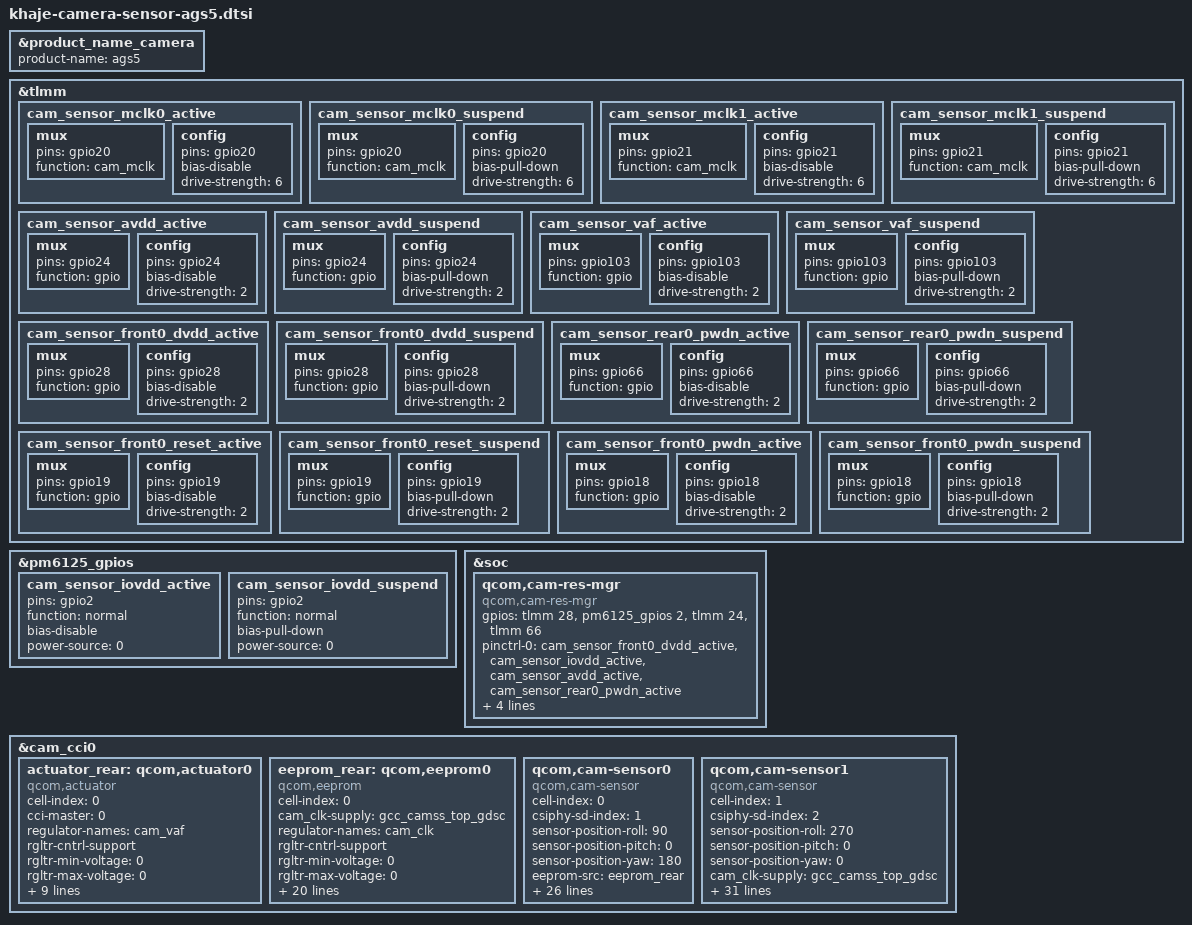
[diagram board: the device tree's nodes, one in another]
#include <dt-bindings/clock/qcom,gcc-khaje.h>
#include <dt-bindings/msm/msm-camera.h>

&product_name_camera {
	product-name = "ags5";
};

&tlmm {
	cam_sensor_mclk0_active: cam_sensor_mclk0_active {
		/* MCLK 0*/
		mux {
			pins = "gpio20";
			function = "cam_mclk";
		};

		config {
			pins = "gpio20";
			bias-disable; /* No PULL */
			drive-strength = <6>; /* 6 MA */
		};
	};

	cam_sensor_mclk0_suspend: cam_sensor_mclk0_suspend {
		/* MCLK 0*/
		mux {
			pins = "gpio20";
			function = "cam_mclk";
		};

		config {
			pins = "gpio20";
			bias-pull-down; /* PULL DOWN */
			drive-strength = <6>; /* 6 MA */
		};
	};

	cam_sensor_mclk1_active: cam_sensor_mclk1_active {
		/* MCLK 1*/
		mux {
			pins = "gpio21";
			function = "cam_mclk";
		};

		config {
			pins = "gpio21";
			bias-disable; /* No PULL */
			drive-strength = <6>; /* 6 MA */
		};
	};

	cam_sensor_mclk1_suspend: cam_sensor_mclk1_suspend {
		/* MCLK 1*/
		mux {
			pins = "gpio21";
			function = "cam_mclk";
		};

		config {
			pins = "gpio21";
			bias-pull-down; /* PULL DOWN */
			drive-strength = <6>; /* 6 MA */
		};
	};

	cam_sensor_avdd_active: cam_sensor_avdd_active {
		/* front and wide DVDD enable*/
		mux {
			pins = "gpio24";
			function = "gpio";
		};

		config {
			pins = "gpio24";
			bias-disable; /* No PULL */
			drive-strength = <2>; /* 2 MA */
		};
	};

	cam_sensor_avdd_suspend: cam_sensor_avdd_suspend {
		/* front and wide DVDD */
		mux {
			pins = "gpio24";
			function = "gpio";
		};

		config {
			pins = "gpio24";
			bias-pull-down; /* PULL DOWN */
			drive-strength = <2>; /* 2 MA */
		};
	};

	cam_sensor_vaf_active: cam_sensor_vaf_active {
		/* DOVDD */
		mux {
			pins = "gpio103";
			function = "gpio";
		};

		config {
			pins = "gpio103";
			bias-disable; /* No PULL */
			drive-strength = <2>; /* 2 MA */
		};
	};

	cam_sensor_vaf_suspend: cam_sensor_vaf_suspend {
		/* DOVDD */
		mux {
			pins = "gpio103";
			function = "gpio";
		};

		config {
			pins = "gpio103";
			bias-pull-down; /* PULL DOWN */
			drive-strength = <2>; /* 2 MA */
		};
	};

	cam_sensor_front0_dvdd_active: cam_sensor_front0_dvdd_active {
		/* dvdd_change */
		mux {
			pins = "gpio28";
			function = "gpio";
		};

		config {
			pins = "gpio28";
			bias-disable; /* No PULL */
			drive-strength = <2>; /* 2 MA */
		};
	};

	cam_sensor_front0_dvdd_suspend: cam_sensor_front0_dvdd_suspend {
		/* dvdd_change */
		mux {
			pins = "gpio28";
			function = "gpio";
		};

		config {
			pins = "gpio28";
			bias-pull-down; /* No PULL */
			drive-strength = <2>; /* 2 MA */
		};
	};

	cam_sensor_rear0_pwdn_active: cam_sensor_rear0_pwdn_active {
		mux {
			pins = "gpio66";
			function = "gpio";
		};

		config {
			pins = "gpio66";
			bias-disable; /* No PULL */
			drive-strength = <2>; /* 2 MA */
		};
	};

	cam_sensor_rear0_pwdn_suspend: cam_sensor_rear0_pwdn_suspend {
		mux {
			pins = "gpio66";
			function = "gpio";
		};

		config {
			pins = "gpio66";
			bias-pull-down; /* PULL DOWN*/
			drive-strength = <2>; /* 2 MA */
		};
	};

	cam_sensor_front0_reset_active: cam_sensor_front0_reset_active {
		mux {
			pins = "gpio19";
			function = "gpio";
		};

		config {
			pins = "gpio19";
			bias-disable; /* No PULL */
			drive-strength = <2>; /* 2 MA */
		};
	};

	cam_sensor_front0_reset_suspend: cam_sensor_front0_reset_suspend {
		mux {
			pins = "gpio19";
			function = "gpio";
		};

		config {
			pins = "gpio19";
			bias-pull-down; /* PULL DOWN*/
			drive-strength = <2>; /* 2 MA */
		};
	};

	cam_sensor_front0_pwdn_active: cam_sensor_front0_pwdn_active {
		mux {
			pins = "gpio18";
			function = "gpio";
		};

		config {
			pins = "gpio18";
			bias-disable; /* No PULL */
			drive-strength = <2>; /* 2 MA */
		};
	};

	cam_sensor_front0_pwdn_suspend: cam_sensor_front0_pwdn_suspend {
		mux {
			pins = "gpio18";
			function = "gpio";
		};

		config {
			pins = "gpio18";
			bias-pull-down; /* PULL DOWN*/
			drive-strength = <2>; /* 2 MA */
		};
	};
};


&pm6125_gpios {
	cam_sensor_iovdd_active: cam_sensor_iovdd_active {
		pins = "gpio2";
		function = "normal";
		bias-disable;
		power-source = <0>;
	};

	cam_sensor_iovdd_suspend: cam_sensor_iovdd_suspend {
		pins = "gpio2";
		function = "normal";
		bias-pull-down;
		power-source = <0>;
	};
};

&soc {
	 qcom,cam-res-mgr {
		compatible = "qcom,cam-res-mgr";
		status = "ok";
		gpios = <&tlmm 28 0>,
			<&pm6125_gpios 2 0>,
			<&tlmm 24 0>,
			<&tlmm 66 0>;
		pinctrl-names = "cam_res_mgr_default", "cam_res_mgr_suspend";
		pinctrl-0 = <&cam_sensor_front0_dvdd_active
				&cam_sensor_iovdd_active
				&cam_sensor_avdd_active
				&cam_sensor_rear0_pwdn_active>;
		pinctrl-1 = <&cam_sensor_front0_dvdd_suspend
				&cam_sensor_iovdd_suspend
				&cam_sensor_avdd_suspend
				&cam_sensor_rear0_pwdn_suspend>;
	 };

};

&cam_cci0 {

	actuator_rear: qcom,actuator0 {
		cell-index = <0>;
		compatible = "qcom,actuator";
		cci-master = <0>;
		regulator-names = "cam_vaf";
		rgltr-cntrl-support;
		rgltr-min-voltage = <0>;
		rgltr-max-voltage = <0>;
		rgltr-load-current = <0>;
		gpio-no-mux = <0>;
		pinctrl-names = "cam_default", "cam_suspend";
		pinctrl-0 = <&cam_sensor_vaf_active>;
		pinctrl-1 = <&cam_sensor_vaf_suspend>;
		gpios = <&tlmm 103 0>;
		gpio-reset = <0>;
		gpio-req-tbl-num = <0>;
		gpio-req-tbl-flags = <0>;
		gpio-req-tbl-label = "CAM_VAF0";
		status = "ok";

	};

// Rear OTP
	eeprom_rear: qcom,eeprom0 {
		cell-index = <0>;
		compatible = "qcom,eeprom";
		cam_clk-supply = <&gcc_camss_top_gdsc>;
		regulator-names = "cam_clk";
		rgltr-cntrl-support;
		rgltr-min-voltage = <0>;
		rgltr-max-voltage = <0>;
		rgltr-load-current = <0>;
		gpio-no-mux = <0>;
		pinctrl-names = "cam_default", "cam_suspend";
		pinctrl-0 = <&cam_sensor_mclk0_active>;
		pinctrl-1 = <&cam_sensor_mclk0_suspend>;
		gpios = <&tlmm 20 0>,
			<&tlmm 66 0>,
			<&tlmm 28 0>,
			<&pm6125_gpios 2 0>,
			<&tlmm 24 0>;
		gpio-reset = <1>;
		gpio-custom1 = <2>;
		gpio-custom2 = <3>;
		gpio-custom-vana = <4>;
		gpio-req-tbl-num = <0 1 2  3 4>;
		gpio-req-tbl-flags = <1 0 0 0 0>;
		gpio-req-tbl-label = "CAMIF_MCLK0",
					"CAM_RESET0",
					"CAM_DVDD0",
					"CAM_IOVDD0",
					"CAM_AVDD0";
		sensor-mode = <0>;
		cci-master = <0>;
		status = "ok";
		clocks = <&gcc GCC_CAMSS_MCLK0_CLK>;
		clock-names = "cam_clk";
		clock-cntl-level = "turbo";
		clock-rates = <24000000>;
		ic_position = <0>; /* CAMERA_POSITION_REAR */
	};


// Rear
	qcom,cam-sensor0 {
		cell-index = <0>;
		compatible = "qcom,cam-sensor";
		csiphy-sd-index = <1>;
		sensor-position-roll = <90>;
		sensor-position-pitch = <0>;
		sensor-position-yaw = <180>;
		eeprom-src = <&eeprom_rear>;
		actuator-src = <&actuator_rear>;
		cam_clk-supply = <&gcc_camss_top_gdsc>;
		regulator-names = "cam_clk";
		rgltr-cntrl-support;
		rgltr-min-voltage = <0>;
		rgltr-max-voltage = <0>;
		rgltr-load-current = <0>;
		gpio-no-mux = <0>;
		pinctrl-names = "cam_default", "cam_suspend";
		pinctrl-0 = <&cam_sensor_mclk0_active>;
		pinctrl-1 = <&cam_sensor_mclk0_suspend>;
		gpios = <&tlmm 20 0>,
			<&tlmm 66 0>,
			<&tlmm 28 0>,
			<&pm6125_gpios 2 0>,
			<&tlmm 24 0>;
		gpio-reset = <1>;
		gpio-custom1 = <2>;
		gpio-custom2 = <3>;
		gpio-custom-vana = <4>;
		gpio-req-tbl-num = <0 1 2  3 4>;
		gpio-req-tbl-flags = <1 0 0 0 0>;
		gpio-req-tbl-label = "CAMIF_MCLK0",
					"CAM_RESET0",
					"CAM_DVDD0",
					"CAM_IOVDD0",
					"CAM_AVDD0";
		sensor-mode = <0>;
		cci-master = <0>;
		status = "ok";
		clocks = <&gcc GCC_CAMSS_MCLK0_CLK>;
		clock-names = "cam_clk";
		clock-cntl-level = "turbo";
		clock-rates = <24000000>;
		ic_position = <0>; /* CAMERA_POSITION_REAR */
	};

//Front
	qcom,cam-sensor1 {
		cell-index = <1>;
		compatible = "qcom,cam-sensor";
		csiphy-sd-index = <2>;
		sensor-position-roll = <270>;
		sensor-position-pitch = <0>;
		sensor-position-yaw = <0>;
		cam_clk-supply = <&gcc_camss_top_gdsc>;
		regulator-names = "cam_clk";
		rgltr-cntrl-support;
		rgltr-min-voltage = <0>;
		rgltr-max-voltage = <0>;
		rgltr-load-current = <0>;
		gpio-no-mux = <0>;
		pinctrl-names = "cam_default", "cam_suspend";
		pinctrl-0 = <&cam_sensor_mclk1_active
				&cam_sensor_front0_reset_active
				&cam_sensor_front0_pwdn_active>;
		pinctrl-1 = <&cam_sensor_mclk1_suspend
				&cam_sensor_front0_reset_suspend
				&cam_sensor_front0_pwdn_suspend>;
		gpios = <&tlmm 21 0>,
			<&tlmm 19 0>,
			<&tlmm 18 0>,
			<&tlmm 28 0>,
			<&pm6125_gpios 2 0>,
			<&tlmm 24 0>,
			<&tlmm 66 0>;
		gpio-reset = <1>;
		gpio-standby = <2>;
		gpio-custom1 = <3>;
		gpio-custom-vio = <4>;
		gpio-custom-vana = <5>;
		gpio-custom2 = <6>;
		gpio-req-tbl-num = <0 1 2 3 4 5 6>;
		gpio-req-tbl-flags = <1 0 0 0 0 0 0>;
		gpio-req-tbl-label = "CAMIF_MCLK1",
					"CAM_RESET1",
					"CAM_PWDN1",
					"CAM_DVDD1",
					"CAM_IOVDD1",
					"CAM_AVDD1",
					"CAM_CUST2";
		sensor-mode = <0>;
		cci-master = <1>;
		status = "ok";
		clocks = <&gcc GCC_CAMSS_MCLK1_CLK>;
		clock-names = "cam_clk";
		clock-cntl-level = "turbo";
		clock-rates = <24000000>;
		ic_position = <1>; /* CAMERA_POSITION_REAR_SECOND */
	};

};

